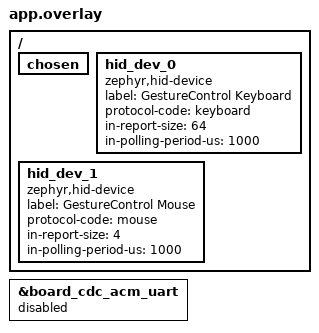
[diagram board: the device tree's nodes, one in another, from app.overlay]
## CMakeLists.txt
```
cmake_minimum_required(VERSION 3.20.0)

find_package(Zephyr REQUIRED HINTS $ENV{ZEPHYR_BASE})

project(receiver_nrf)

target_sources(app PRIVATE 
    src/main.c
    src/usb_hid.c
    ../common/gesture_config.c
)

target_include_directories(app PRIVATE
    ${CMAKE_CURRENT_SOURCE_DIR}/../common
)
```

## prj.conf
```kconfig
CONFIG_GPIO=y

CONFIG_LOG=y
CONFIG_LOG_DEFAULT_LEVEL=3

CONFIG_BT=y
CONFIG_BT_PERIPHERAL=y
CONFIG_BT_DEVICE_NAME="MyoPC"
CONFIG_BT_MAX_CONN=2

# USB HID device
CONFIG_USB_DEVICE_STACK_NEXT=y
CONFIG_USBD_HID_SUPPORT=y

CONFIG_CONSOLE=n
CONFIG_UART_CONSOLE=n
CONFIG_LOG_BACKEND_UART=n
```

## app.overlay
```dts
/ {
    chosen {
        /delete-property/ zephyr,console;
        /delete-property/ zephyr,shell-uart;
        /delete-property/ zephyr,uart-mcumgr;
        /delete-property/ zephyr,bt-mon-uart;
        /delete-property/ zephyr,bt-c2h-uart;
    };

    hid_dev_0: hid_dev_0 {
        compatible = "zephyr,hid-device";
        label = "GestureControl Keyboard";

        protocol-code = "keyboard";

        in-report-size = <64>;
        in-polling-period-us = <1000>;
    };

    hid_dev_1: hid_dev_1 {
        compatible = "zephyr,hid-device";
        label = "GestureControl Mouse";

        protocol-code = "mouse";

        in-report-size = <4>;
        in-polling-period-us = <1000>;
    };
};

&board_cdc_acm_uart {
    status = "disabled";
};
```

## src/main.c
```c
#include <zephyr/kernel.h>
#include <zephyr/device.h>
#include <zephyr/drivers/gpio.h>
#include <zephyr/logging/log.h>
#include <zephyr/sys/atomic.h>
#include <zephyr/bluetooth/bluetooth.h>
#include <zephyr/bluetooth/conn.h>
#include <zephyr/bluetooth/gatt.h>
#include <zephyr/bluetooth/uuid.h>
#include <errno.h>

#include <string.h>
#include "myo_ble.h"
#include "gesture_config.h"
#include "receiver_links.h"
#include "usb_hid.h"


LOG_MODULE_REGISTER(receiver, LOG_LEVEL_INF);

#define ADV_RETRY_MS 250
#define LED_NODE DT_ALIAS(led0)
#define RX_TIMEOUT_MS 1500
#define TENSE_GUARD_MS 250

static const struct gpio_dt_spec led =
    GPIO_DT_SPEC_GET(LED_NODE, gpios);

static atomic_t link_up;
static atomic_t advertising_needed;
static struct gc_receiver_links rx_links;
static atomic_t rx_valid;
static atomic_t last_rx_ms;
static atomic_t session_epoch;

// A small event queue separates BLE callbacks
// from physical actuation.
struct queued_gesture {
    struct myo_gesture_packet packet;
    uint32_t session;
    uint32_t timestamp_ms;
};

K_MSGQ_DEFINE(
    gesture_queue,
    sizeof(struct queued_gesture),
    8,
    4
);

/* Called on the first validated gesture-side GATT write. */
static void begin_gesture_session(void);

static bool accept_gesture_peer(struct bt_conn *conn)
{
    enum gc_claim_result result =
        gc_links_claim(&rx_links, conn, GC_PEER_GESTURE);
    if (result == GC_CLAIM_DENIED) {
        LOG_WRN("Rejected gesture write from other BLE peer");
        return false;
    }
    if (result == GC_CLAIM_NEW) {
        begin_gesture_session();
    }
    return true;
}

static ssize_t config_command_write(
    struct bt_conn *conn, const struct bt_gatt_attr *attr,
    const void *buf, uint16_t len, uint16_t offset, uint8_t flags)
{
    if (gc_links_claim(&rx_links, conn, GC_PEER_CONFIG) ==
        GC_CLAIM_DENIED) {
        return BT_GATT_ERR(BT_ATT_ERR_WRITE_NOT_PERMITTED);
    }
    return gc_config_write(conn, attr, buf, len, offset, flags);
}

static ssize_t config_response_read(
    struct bt_conn *conn, const struct bt_gatt_attr *attr,
    void *buf, uint16_t len, uint16_t offset)
{
    if (gc_links_claim(&rx_links, conn, GC_PEER_CONFIG) ==
        GC_CLAIM_DENIED) {
        return BT_GATT_ERR(BT_ATT_ERR_READ_NOT_PERMITTED);
    }
    return gc_config_read_response(conn, attr, buf, len, offset);
}

static ssize_t config_info_read(
    struct bt_conn *conn, const struct bt_gatt_attr *attr,
    void *buf, uint16_t len, uint16_t offset)
{
    if (gc_links_claim(&rx_links, conn, GC_PEER_CONFIG) ==
        GC_CLAIM_DENIED) {
        return BT_GATT_ERR(BT_ATT_ERR_READ_NOT_PERMITTED);
    }
    return gc_config_read_info(conn, attr, buf, len, offset);
}

// Actuation state, owned by main thread.
static bool sequence_seen;
static uint8_t last_sequence;
static uint32_t processed_session = UINT32_MAX;

static bool tense_seen;
static uint32_t last_tense_ms;

// Gesture helpers
static const char *gesture_name(uint8_t gesture)
{
    switch (gesture) {
    case MYO_GESTURE_SWIPE_UP:
        return "SWIPE_UP";

    case MYO_GESTURE_SWIPE_DOWN:
        return "SWIPE_DOWN";

    case MYO_GESTURE_SWIPE_LEFT:
        return "SWIPE_LEFT";

    case MYO_GESTURE_SWIPE_RIGHT:
        return "SWIPE_RIGHT";

    case MYO_GESTURE_TENSE:
        return "TENSE";

    case MYO_GESTURE_EXTEND:
        return "EXTEND";

    case MYO_GESTURE_FLEX:
        return "FLEX";

    default:
        return "UNKNOWN";
    }
}

// Legacy validity characteristic
static ssize_t write_state(
    struct bt_conn *conn,
    const struct bt_gatt_attr *attr,
    const void *buf,
    uint16_t len,
    uint16_t offset,
    uint8_t flags)
{
    ARG_UNUSED(attr);

    if (offset != 0 || len != 1) {
        return BT_GATT_ERR(
            BT_ATT_ERR_INVALID_ATTRIBUTE_LEN);
    }

    if (flags & BT_GATT_WRITE_FLAG_PREPARE) {
        return 0;
    }

    uint8_t state = ((const uint8_t *)buf)[0];

    if (state != MYO_VALID && state != MYO_INVALID) {
        return BT_GATT_ERR(BT_ATT_ERR_UNLIKELY);
    }

    if (!accept_gesture_peer(conn)) {
        return BT_GATT_ERR(BT_ATT_ERR_WRITE_NOT_PERMITTED);
    }

    atomic_set(&rx_valid, state == MYO_VALID);
    atomic_set(&last_rx_ms, k_uptime_get_32());

// Do not switch back to legacy LED mode here.
// Once a gesture controls the LED, its state persists.
    LOG_INF("Received: %s",
            state == MYO_VALID ? "VALID" : "INVALID");

    return len;
}

// Receives classified gesture events.
static ssize_t write_gesture(
    struct bt_conn *conn,
    const struct bt_gatt_attr *attr,
    const void *buf,
    uint16_t len,
    uint16_t offset,
    uint8_t flags)
{
    ARG_UNUSED(attr);

    if (offset != 0 ||
        len != sizeof(struct myo_gesture_packet)) {
        return BT_GATT_ERR(
            BT_ATT_ERR_INVALID_ATTRIBUTE_LEN);
    }

    if (flags & BT_GATT_WRITE_FLAG_PREPARE) {
        return 0;
    }

   struct queued_gesture event;

    memcpy(&event.packet, buf, sizeof(event.packet));

    if (!myo_gesture_valid(event.packet.gesture)) {
        LOG_WRN("Invalid gesture ID: %u",
                event.packet.gesture);

        return BT_GATT_ERR(
            BT_ATT_ERR_VALUE_NOT_ALLOWED);
    }

    if (!accept_gesture_peer(conn)) {
        return BT_GATT_ERR(BT_ATT_ERR_WRITE_NOT_PERMITTED);
    }

    event.session =
        (uint32_t)atomic_get(&session_epoch);

    event.timestamp_ms = k_uptime_get_32();

    if (k_msgq_put(
            &gesture_queue, &event, K_NO_WAIT) != 0) {

        LOG_WRN("Gesture queue full");

        return BT_GATT_ERR(
            BT_ATT_ERR_INSUFFICIENT_RESOURCES);
    }

    return len;
}


// Custom GestureControl GATT service
BT_GATT_SERVICE_DEFINE(myo_service,
    BT_GATT_PRIMARY_SERVICE(
        BT_UUID_DECLARE_128(MYO_SERVICE_UUID_BYTES)),

    BT_GATT_CHARACTERISTIC(
        BT_UUID_DECLARE_128(MYO_STATE_UUID_BYTES),
        BT_GATT_CHRC_WRITE |
        BT_GATT_CHRC_WRITE_WITHOUT_RESP,
        BT_GATT_PERM_WRITE,
        NULL,
        write_state,
        NULL),
    
     BT_GATT_CHARACTERISTIC(
        BT_UUID_DECLARE_128(MYO_GESTURE_UUID_BYTES),
        BT_GATT_CHRC_WRITE |
        BT_GATT_CHRC_WRITE_WITHOUT_RESP,
        BT_GATT_PERM_WRITE,
        NULL,
        write_gesture,
        NULL),

    BT_GATT_CHARACTERISTIC(
        BT_UUID_DECLARE_128(GC_CONFIG_COMMAND_UUID_BYTES),
        BT_GATT_CHRC_WRITE,
        BT_GATT_PERM_WRITE,
        NULL,
        config_command_write,
        NULL),

    BT_GATT_CHARACTERISTIC(
        BT_UUID_DECLARE_128(GC_CONFIG_RESPONSE_UUID_BYTES),
        BT_GATT_CHRC_READ,
        BT_GATT_PERM_READ,
        config_response_read,
        NULL,
        NULL),

    BT_GATT_CHARACTERISTIC(
        BT_UUID_DECLARE_128(GC_CONFIG_INFO_UUID_BYTES),
        BT_GATT_CHRC_READ,
        BT_GATT_PERM_READ,
        config_info_read,
        NULL,
        NULL)
);

// Put UUID in advertisements so Sense can find this
static const struct bt_data ad[] = {
    BT_DATA_BYTES(
        BT_DATA_FLAGS,
        BT_LE_AD_GENERAL | BT_LE_AD_NO_BREDR),

    BT_DATA_BYTES(
        BT_DATA_UUID128_ALL,
        MYO_SERVICE_UUID_BYTES),

    BT_DATA_BYTES(
        BT_DATA_NAME_COMPLETE,
        'M', 'y', 'o', 'P', 'C'),
};

static int start_advertising(void)
{
    int err = bt_le_adv_start(
        BT_LE_ADV_CONN_FAST_1,
        ad, ARRAY_SIZE(ad),
        NULL, 0);

    if (err == -EALREADY) {
        return 0;
    }

    if (err == -ENOMEM) {
        /* Connection resources not yet recycled. */
        return err;
    }
    if (err) {
        LOG_WRN("Advertising failed: %d, retrying", err);
        return err;
    }

    LOG_INF("Advertising as MyoPC");
    return 0;
}

static void begin_gesture_session(void)
{
    atomic_inc(&session_epoch);
    k_msgq_purge(&gesture_queue);
    atomic_set(&rx_valid, 0);
    atomic_set(&last_rx_ms, 0);
    atomic_set(&link_up, 1);
    LOG_INF("MyoPC gesture controller active");
}

static void connected(struct bt_conn *conn, uint8_t err)
{
    ARG_UNUSED(conn);
    if (err) {
        LOG_ERR("Connection failed: %u", err);
        atomic_set(&advertising_needed, 1);
        return;
    }
    gc_links_connected(&rx_links);
    atomic_set(&advertising_needed, 1);
    LOG_INF("BLE peer connected (%d/%d)",
            gc_links_count(&rx_links), CONFIG_BT_MAX_CONN);
}

static void disconnected(struct bt_conn *conn, uint8_t reason)
{
    bool gesture_lost = gc_links_disconnected(&rx_links, conn);
    if (gesture_lost) {
        atomic_set(&link_up, 0);
        atomic_set(&rx_valid, 0);
        atomic_inc(&session_epoch);
        k_msgq_purge(&gesture_queue);
        myo_usb_hid_release_all();
        LOG_INF("Gesture controller disconnected");
    } else {
        LOG_INF("Configuration/unclaimed peer disconnected");
    }
    LOG_INF("BLE disconnect reason: %u", reason);
    atomic_set(&advertising_needed, 1);
}

static void recycled(void)
{
    /* Retry advertising in main loop after a connection is freed. */
    atomic_set(&advertising_needed, 1);
}

BT_CONN_CB_DEFINE(conn_callbacks) = {
    .connected = connected,
    .disconnected = disconnected,
    .recycled = recycled,
};

// Gesture actuation dispatcher
static void process_gesture(
    const struct queued_gesture *event)
{
    if (!atomic_get(&link_up) ||
        event->session !=
            (uint32_t)atomic_get(&session_epoch)) {
        return;
    }

    // New BLE session: reset duplicate tracking.
    if (event->session != processed_session) {
        processed_session = event->session;

        sequence_seen = false;
        tense_seen = false;
    }

    uint8_t gesture = event->packet.gesture;
    uint8_t sequence = event->packet.sequence;

    // Reject repeated packets carrying the
    // same sequence number.
    if (sequence_seen && sequence == last_sequence) {
        LOG_WRN("Duplicate packet: seq=%u", sequence);
        return;
    }

    sequence_seen = true;
    last_sequence = sequence;

    LOG_INF("Gesture: %s seq=%u",
            gesture_name(gesture), sequence);

    if (gesture == MYO_GESTURE_TENSE) {
        if (tense_seen &&
            (uint32_t)(event->timestamp_ms -
                       last_tense_ms) < TENSE_GUARD_MS) {
            LOG_INF("TENSE suppressed by cooldown");
            return;
        }

        tense_seen = true;
        last_tense_ms = event->timestamp_ms;

    }

    struct gc_mapping mapping = gc_config_get(gesture);
    int hid_err = myo_usb_hid_enqueue(gesture, &mapping);

    if (hid_err == -ENOTCONN) {
        LOG_DBG("USB not connected, HID skipped");
    } else if (hid_err) {
        LOG_WRN("HID enqueue failed: %d", hid_err);
    }
}

// Status LED is independent of HID and gesture mappings.
static void update_led(void)
{
    uint32_t now = k_uptime_get_32();
    uint32_t phase = now % 1200U;
    bool connected = atomic_get(&link_up) != 0;
    bool fresh = connected &&
        (uint32_t)(now - (uint32_t)atomic_get(&last_rx_ms))
            < RX_TIMEOUT_MS;
    bool valid = atomic_get(&rx_valid) != 0;

    bool on;
    if (!connected) {
        on = phase < 120U;
    } else if (!fresh) {
        on = phase < 120U ||
             (phase >= 280U && phase < 400U);
    } else if (!valid) {
        on = phase < 500U;
    } else {
        on = true;
    }

    static int last = -1;
    int requested = on ? 1 : 0;
    if (requested != last) {
        int err = gpio_pin_set_dt(&led, requested);
        if (!err) {
            last = requested;
        } else {
            LOG_WRN("Status LED update failed: %d", err);
        }
    }
}

int main(void)
{
    if (!gpio_is_ready_dt(&led)) {
        LOG_ERR("LED not ready");
        return 0;
    }

    gpio_pin_configure_dt(
        &led, GPIO_OUTPUT_INACTIVE);

    
    LOG_INF("GestureControl receiver starting");

    gc_config_init(GC_TARGET_COMPUTER);

    int err = myo_usb_hid_init();

    if (err) {
        LOG_ERR("USB HID init failed: %d", err);
    }

    gc_links_init(&rx_links);

    err = bt_enable(NULL);

    if (err) {
        LOG_ERR("Bluetooth init failed: %d", err);
        return 0;
    }

    atomic_set(&advertising_needed, 1);

    uint32_t next_adv_retry_ms = 0;

    while (1) {
        struct queued_gesture event;

        // Process BLE events in the main thread.
        if (k_msgq_get(
                &gesture_queue,
                &event,
                K_MSEC(25)) == 0) {

            process_gesture(&event);
        }

        uint32_t now = k_uptime_get_32();

        if (atomic_get(&advertising_needed) &&
            gc_links_count(&rx_links) < CONFIG_BT_MAX_CONN &&
            (int32_t)(now - next_adv_retry_ms) >= 0) {

            next_adv_retry_ms = now + ADV_RETRY_MS;

            if (start_advertising() == 0) {
                atomic_set(&advertising_needed, 0);
            }
        }
        // Update the physical output independently.
        update_led();
    }

    return 0;
}
```

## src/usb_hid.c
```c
#include "usb_hid.h"

#include <errno.h>
#include <stdint.h>
#include <string.h>

#include <zephyr/kernel.h>
#include <zephyr/device.h>
#include <zephyr/sys/atomic.h>
#include <zephyr/logging/log.h>
#include <zephyr/usb/usbd.h>
#include <zephyr/usb/class/usbd_hid.h>
#include <zephyr/usb/class/hid.h>

LOG_MODULE_REGISTER(myo_usb, LOG_LEVEL_INF);

#define MYO_USB_VID 0xCAFE
#define MYO_USB_PID 0x4015

#define KEYBOARD_REPORT_SIZE 8
#define MOUSE_REPORT_SIZE 4

#define MOUSE_BUTTON_LEFT   0x01
#define MOUSE_BUTTON_RIGHT  0x02
#define MOUSE_BUTTON_MIDDLE 0x04

static const uint8_t keyboard_report_desc[] =
    HID_KEYBOARD_REPORT_DESC();

static const uint8_t mouse_report_desc[] =
    HID_MOUSE_REPORT_DESC(3);

static const struct device *const keyboard_dev =
    DEVICE_DT_GET(DT_NODELABEL(hid_dev_0));

static const struct device *const mouse_dev =
    DEVICE_DT_GET(DT_NODELABEL(hid_dev_1));

USBD_DEVICE_DEFINE(
    myo_usbd,
    DEVICE_DT_GET(DT_NODELABEL(zephyr_udc0)),
    MYO_USB_VID,
    MYO_USB_PID
);

USBD_DESC_LANG_DEFINE(myo_lang);

USBD_DESC_MANUFACTURER_DEFINE(
    myo_mfr, "GestureControl");

USBD_DESC_PRODUCT_DEFINE(
    myo_product, "GestureControl Keyboard and Mouse");

USBD_DESC_CONFIG_DEFINE(
    myo_cfg_desc, "GestureControl HID Configuration");

USBD_CONFIGURATION_DEFINE(
    myo_fs_cfg,
    0,
    50,
    &myo_cfg_desc
);

static atomic_t keyboard_ready;
static atomic_t mouse_ready;
static atomic_t release_requested;

/* HID worker owns these five independent gesture toggles. */
static uint8_t toggle_keys[GC_GESTURE_COUNT + 1];
static uint8_t toggle_modifiers[GC_GESTURE_COUNT + 1];

static uint32_t idle_ms[4];

struct queued_hid_action {
    uint8_t gesture;
    struct gc_mapping mapping;
};

K_MSGQ_DEFINE(
    hid_action_queue,
    sizeof(struct queued_hid_action),
    12,
    4
);

static void keyboard_iface_ready(
    const struct device *dev,
    bool ready)
{
    ARG_UNUSED(dev);

    atomic_set(&keyboard_ready, ready ? 1 : 0);

    if (!ready) {
        k_msgq_purge(&hid_action_queue);
        atomic_set(&release_requested, 1);
    }

    LOG_INF("Keyboard HID %s",
            ready ? "ready" : "not ready");
}

static void mouse_iface_ready(
    const struct device *dev,
    bool ready)
{
    ARG_UNUSED(dev);

    atomic_set(&mouse_ready, ready ? 1 : 0);

    LOG_INF("Mouse HID %s",
            ready ? "ready" : "not ready");
}

static int keyboard_get_report(
    const struct device *dev,
    uint8_t type,
    uint8_t id,
    uint16_t len,
    uint8_t *buf)
{
    ARG_UNUSED(dev);

    if (type != HID_REPORT_TYPE_INPUT || id != 0) {
        return -ENOTSUP;
    }

    if (len < KEYBOARD_REPORT_SIZE) {
        return -ENOBUFS;
    }

    memset(buf, 0, KEYBOARD_REPORT_SIZE);

    return KEYBOARD_REPORT_SIZE;
}

static int mouse_get_report(
    const struct device *dev,
    uint8_t type,
    uint8_t id,
    uint16_t len,
    uint8_t *buf)
{
    ARG_UNUSED(dev);

    if (type != HID_REPORT_TYPE_INPUT || id != 0) {
        return -ENOTSUP;
    }

    if (len < MOUSE_REPORT_SIZE) {
        return -ENOBUFS;
    }

    memset(buf, 0, MOUSE_REPORT_SIZE);

    return MOUSE_REPORT_SIZE;
}

static void hid_set_idle(
    const struct device *dev,
    uint8_t id,
    uint32_t duration)
{
    ARG_UNUSED(dev);

    if (id == 0) {
        for (int i = 1; i <= 3; i++) {
            idle_ms[i] = duration;
        }
    } else if (id <= 3) {
        idle_ms[id] = duration;
    }
}

static uint32_t hid_get_idle(
    const struct device *dev,
    uint8_t id)
{
    ARG_UNUSED(dev);

    return id <= 3 ? idle_ms[id] : 0;
}

static void keyboard_set_protocol(
    const struct device *dev,
    uint8_t protocol)
{
    ARG_UNUSED(dev);

    LOG_INF("Keyboard protocol: %u", protocol);
}

static void mouse_set_protocol(
    const struct device *dev,
    uint8_t protocol)
{
    ARG_UNUSED(dev);

    LOG_INF("Mouse protocol: %u", protocol);
}

static int keyboard_set_report(
    const struct device *dev,
    uint8_t type,
    uint8_t id,
    uint16_t len,
    const uint8_t *buf)
{
    ARG_UNUSED(dev);
    ARG_UNUSED(buf);

    if (type == HID_REPORT_TYPE_OUTPUT &&
        id == 0 &&
        len == 1) {
        return 0;
    }

    return -ENOTSUP;
}

static const struct hid_device_ops keyboard_ops = {
    .iface_ready = keyboard_iface_ready,
    .get_report = keyboard_get_report,
    .set_report = keyboard_set_report,
    .set_idle = hid_set_idle,
    .get_idle = hid_get_idle,
    .set_protocol = keyboard_set_protocol,
};

static const struct hid_device_ops mouse_ops = {
    .iface_ready = mouse_iface_ready,
    .get_report = mouse_get_report,
    .set_idle = hid_set_idle,
    .get_idle = hid_get_idle,
    .set_protocol = mouse_set_protocol,
};

static void usb_msg_cb(
    struct usbd_context *const ctx,
    const struct usbd_msg *const msg)
{
    if (msg->type == USBD_MSG_VBUS_READY) {
        int err = usbd_enable(ctx);

        if (err) {
            LOG_ERR("USB enable failed: %d", err);
        }
    }

    if (msg->type == USBD_MSG_VBUS_REMOVED) {
        atomic_set(&keyboard_ready, 0);
        atomic_set(&mouse_ready, 0);

        k_msgq_purge(&hid_action_queue);
        atomic_set(&release_requested, 1);
        int err = usbd_disable(ctx);

        if (err) {
            LOG_ERR("USB disable failed: %d", err);
        }
    }
}

bool usb_hid_ready(void)
{
    return atomic_get(&keyboard_ready) != 0;
}

static bool hid_action_ready(const struct gc_mapping *mapping)
{
    if (mapping->action == GC_ACTION_NONE) {
        return true;
    }

    if (mapping->action == GC_ACTION_KEY_TAP ||
        mapping->action == GC_ACTION_KEY_TOGGLE) {
        return atomic_get(&keyboard_ready) != 0;
    }

    return atomic_get(&mouse_ready) != 0;
}

static int send_report(
    const struct device *dev,
    const uint8_t *report,
    uint16_t length)
{
    if (dev == keyboard_dev &&
        !atomic_get(&keyboard_ready)) {
        return -ENOTCONN;
    }

    if (dev == mouse_dev &&
        !atomic_get(&mouse_ready)) {
        return -ENOTCONN;
    }

    return hid_device_submit_report(
        dev,
        length,
        report
    );
}

/* Combine toggled keys with a temporary tap in one 6-key HID report. */
static int keyboard_send_state(uint8_t temporary_key, uint8_t temporary_mods)
{
    UDC_STATIC_BUF_DEFINE(report, KEYBOARD_REPORT_SIZE);
    memset(report, 0, sizeof(report));
    report[0] = temporary_mods;

    uint8_t used = 0;
    for (uint8_t g = 1; g <= GC_GESTURE_COUNT; g++) {
        uint8_t key = toggle_keys[g];
        if (key == 0) {
            continue;
        }
        report[0] |= toggle_modifiers[g];
        bool found = false;
        for (uint8_t i = 0; i < used; i++) {
            if (report[2 + i] == key) {
                found = true;
                break;
            }
        }
        if (!found && used < 6) {
            report[2 + used++] = key;
        }
    }
    if (temporary_key != 0) {
        bool found = false;
        for (uint8_t i = 0; i < used; i++) {
            if (report[2 + i] == temporary_key) {
                found = true;
                break;
            }
        }
        if (!found && used < 6) {
            report[2 + used] = temporary_key;
        }
    }
    return send_report(keyboard_dev, report, sizeof(report));
}

static void keyboard_release_all(void)
{
    memset(toggle_keys, 0, sizeof(toggle_keys));
    memset(toggle_modifiers, 0, sizeof(toggle_modifiers));
    if (atomic_get(&keyboard_ready)) {
        int err = keyboard_send_state(0, 0);
        if (err) {
            LOG_WRN("Keyboard release failed: %d", err);
        }
    }
}

static int keyboard_toggle(uint8_t gesture, uint8_t key,
                           uint8_t modifiers)
{
    if (gesture == 0 || gesture > GC_GESTURE_COUNT) {
        return -EINVAL;
    }
    uint8_t old_key = toggle_keys[gesture];
    uint8_t old_mods = toggle_modifiers[gesture];
    if (old_key == 0) {
        toggle_keys[gesture] = key;
        toggle_modifiers[gesture] = modifiers;
    } else {
        toggle_keys[gesture] = 0;
        toggle_modifiers[gesture] = 0;
    }
    int err = keyboard_send_state(0, 0);
    if (err) {
        toggle_keys[gesture] = old_key;
        toggle_modifiers[gesture] = old_mods;
        return err;
    }
    k_msleep(15);
    return 0;
}

static int keyboard_tap(uint8_t key,
                        uint8_t modifiers,
                        uint16_t duration_ms)
{
    int err = keyboard_send_state(key, modifiers);
    if (err) {
        return err;
    }
    k_msleep(duration_ms);
    /* Keep toggles pressed after the short-lived tap releases. */
    err = keyboard_send_state(0, 0);
    if (err) {
        return err;
    }
    k_msleep(15);
    return 0;
}

static int mouse_move(int8_t dx, int8_t dy)
{
    UDC_STATIC_BUF_DEFINE(report, MOUSE_REPORT_SIZE);

    memset(report, 0, sizeof(report));
    report[1] = (uint8_t)dx;
    report[2] = (uint8_t)dy;

    return send_report(mouse_dev, report, sizeof(report));
}

static int mouse_scroll(int8_t amount)
{
    UDC_STATIC_BUF_DEFINE(report, MOUSE_REPORT_SIZE);

    memset(report, 0, sizeof(report));
    report[3] = (uint8_t)amount;

    return send_report(mouse_dev, report, sizeof(report));
}

static int mouse_click(uint8_t button,
                       uint8_t count,
                       uint16_t duration_ms)
{
    UDC_STATIC_BUF_DEFINE(report, MOUSE_REPORT_SIZE);

    for (uint8_t i = 0; i < count; i++) {
        memset(report, 0, sizeof(report));
        report[0] = button;

        int err = send_report(mouse_dev, report, sizeof(report));
        if (err) {
            return err;
        }

        k_msleep(duration_ms);

        // Release the mouse button after every click.
        memset(report, 0, sizeof(report));
        err = send_report(mouse_dev, report, sizeof(report));
        if (err) {
            return err;
        }

        k_msleep(count == 2 && i == 0 ? 80 : 15);
    }

    return 0;
}

static int execute_hid_action(uint8_t gesture,
                              const struct gc_mapping *mapping)
{
    int8_t amount = (int8_t)mapping->amount;

    switch (mapping->action) {
    case GC_ACTION_NONE:
        return 0;

    case GC_ACTION_KEY_TAP:
        return keyboard_tap(mapping->keycode,
                            mapping->modifiers,
                            mapping->duration_ms);

    case GC_ACTION_KEY_TOGGLE:
        return keyboard_toggle(gesture, mapping->keycode,
                               mapping->modifiers);

    case GC_ACTION_MOUSE_LEFT_CLICK:
        return mouse_click(MOUSE_BUTTON_LEFT, 1, mapping->duration_ms);

    case GC_ACTION_MOUSE_RIGHT_CLICK:
        return mouse_click(MOUSE_BUTTON_RIGHT, 1, mapping->duration_ms);

    case GC_ACTION_MOUSE_MIDDLE_CLICK:
        return mouse_click(MOUSE_BUTTON_MIDDLE, 1, mapping->duration_ms);

    case GC_ACTION_MOUSE_DOUBLE_CLICK:
        return mouse_click(MOUSE_BUTTON_LEFT, 2, mapping->duration_ms);

    case GC_ACTION_MOUSE_MOVE_UP:
        return mouse_move(0, -amount);

    case GC_ACTION_MOUSE_MOVE_DOWN:
        return mouse_move(0, amount);

    case GC_ACTION_MOUSE_MOVE_LEFT:
        return mouse_move(-amount, 0);

    case GC_ACTION_MOUSE_MOVE_RIGHT:
        return mouse_move(amount, 0);

    case GC_ACTION_MOUSE_SCROLL_UP:
        return mouse_scroll(amount);

    case GC_ACTION_MOUSE_SCROLL_DOWN:
        return mouse_scroll(-amount);

    default:
        return -EINVAL;
    }
}

static void hid_worker(
    void *arg1,
    void *arg2,
    void *arg3)
{
    ARG_UNUSED(arg1);
    ARG_UNUSED(arg2);
    ARG_UNUSED(arg3);

    uint32_t revision = gc_config_revision();
    while (1) {
        uint32_t current_revision = gc_config_revision();
        if (atomic_set(&release_requested, 0) ||
            current_revision != revision) {
            k_msgq_purge(&hid_action_queue);
            keyboard_release_all();
            revision = gc_config_revision();
        }

        struct queued_hid_action event;
        if (k_msgq_get(&hid_action_queue, &event,
                       K_MSEC(20)) != 0) {
            continue;
        }
        if (atomic_get(&release_requested) ||
            gc_config_revision() != revision) {
            continue;
        }
        if (!hid_action_ready(&event.mapping)) {
            continue;
        }
        int err = execute_hid_action(event.gesture, &event.mapping);
        if (err && err != -ENOTCONN) {
            LOG_WRN("HID action %u failed: %d",
                    event.mapping.action, err);
        }
    }
}

K_THREAD_DEFINE(
    hid_worker_id,
    1536,
    hid_worker,
    NULL, NULL, NULL,
    7,
    0,
    0
);

void myo_usb_hid_release_all(void)
{
    k_msgq_purge(&hid_action_queue);
    atomic_set(&release_requested, 1);
}

int myo_usb_hid_enqueue(uint8_t gesture,
                       const struct gc_mapping *mapping)
{
    if (mapping == NULL || gesture == 0 ||
        gesture > GC_GESTURE_COUNT) {
        return -EINVAL;
    }
    if (mapping->action == GC_ACTION_NONE) {
        return 0;
    }
    if (!hid_action_ready(mapping)) {
        return -ENOTCONN;
    }
    struct queued_hid_action event = {
        .gesture = gesture,
        .mapping = *mapping
    };
    return k_msgq_put(&hid_action_queue, &event, K_NO_WAIT);
}

int myo_usb_hid_init(void)
{
    int err;

    if (!device_is_ready(keyboard_dev)) {
        LOG_ERR("Keyboard HID device unavailable");
        return -ENODEV;
    }

    if (!device_is_ready(mouse_dev)) {
        LOG_ERR("Mouse HID device unavailable");
        return -ENODEV;
    }

    err = hid_device_register(
        keyboard_dev,
        keyboard_report_desc,
        sizeof(keyboard_report_desc),
        &keyboard_ops
    );

    if (err) {
        LOG_ERR("Keyboard registration failed: %d", err);
        return err;
    }

    err = hid_device_register(
        mouse_dev,
        mouse_report_desc,
        sizeof(mouse_report_desc),
        &mouse_ops
    );

    if (err) {
        LOG_ERR("Mouse registration failed: %d", err);
        return err;
    }

    err = usbd_add_descriptor(&myo_usbd, &myo_lang);
    if (err) {
        return err;
    }

    err = usbd_add_descriptor(&myo_usbd, &myo_mfr);
    if (err) {
        return err;
    }

    err = usbd_add_descriptor(&myo_usbd, &myo_product);
    if (err) {
        return err;
    }

    err = usbd_add_configuration(
        &myo_usbd,
        USBD_SPEED_FS,
        &myo_fs_cfg
    );

    if (err) {
        return err;
    }

    err = usbd_register_class(
        &myo_usbd,
        "hid_0",
        USBD_SPEED_FS,
        1
    );

    if (err) {
        LOG_ERR("Keyboard class registration failed: %d", err);
        return err;
    }

    err = usbd_register_class(
        &myo_usbd,
        "hid_1",
        USBD_SPEED_FS,
        1
    );

    if (err) {
        LOG_ERR("Mouse class registration failed: %d", err);
        return err;
    }

    err = usbd_msg_register_cb(
        &myo_usbd,
        usb_msg_cb
    );

    if (err) {
        return err;
    }

    err = usbd_init(&myo_usbd);

    if (err) {
        LOG_ERR("USB initialization failed: %d", err);
        return err;
    }

    if (!usbd_can_detect_vbus(&myo_usbd)) {
        err = usbd_enable(&myo_usbd);

        if (err) {
            return err;
        }
    }

    LOG_INF("Keyboard and mouse HID initialized");
    return 0;
}
```

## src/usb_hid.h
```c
#ifndef MYO_USB_HID_H
#define MYO_USB_HID_H

#include <stdbool.h>
#include <stdint.h>
#include "gesture_config.h"

int myo_usb_hid_init(void);
bool usb_hid_ready(void);
int myo_usb_hid_enqueue(uint8_t gesture, const struct gc_mapping *mapping);
void myo_usb_hid_release_all(void);

#endif
```
